# rCSL_emac_001 register map
Vendor: Texas Instruments
Peripheral module from a debugger description file (folder OMAPL138_C6748).
Registers are 32-bit, read-write, reset 0x0 unless marked. A register's access mark holds for its fields unless they carry their own. Offsets are as the file gives them; lines under a group give offsets from that group; [hi:lo] are bit positions; {n}, {i} and the like mark numbered series; 'fields as' and 'values as' point back to an identical list; <NAME> marks a mode.

## EMAC — Common Platform Gigabit ethernet MAC
0x00 TXREVID ro reset 0x4EC0020D — Transmit Identification and Version Register
  [31:0] TXREV
0x04 TXCONTROL access not given — Transmit Control Register
  [0] TXEN rw — Transmit enable
    0=DISABLE (Transmit is disabled); 1=ENABLE (Transmit is enabled)
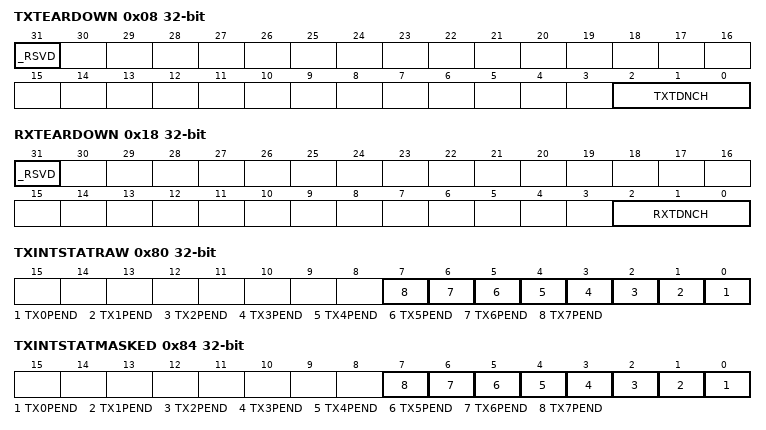
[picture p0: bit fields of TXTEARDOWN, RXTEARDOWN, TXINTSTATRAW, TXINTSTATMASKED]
0x08 TXTEARDOWN access not given — Transmit Teardown Register
  [31] _RSVD — TX teardown ready; read as zero, but always assumed to be one - unused (access N)
  [2:0] TXTDNCH rw — TX teardown channed
    {v}=CHA{v} (v=0..7)
0x10 RXREVID ro reset 0x4EC0020D — RX Identification and Version Register
  [31:0] RXREV
0x14 RXCONTROL access not given
  [0] RXEN rw — RX DMA enable
    0=DISABLE (Receive is disabled); 1=ENABLE (Receive is enabled)
0x18 RXTEARDOWN access not given
  [31] _RSVD — Teardown ready; read as zero, but it is always assumed to be one - unused (access N)
  [2:0] RXTDNCH rw — RX teardown channel
    {v}=CHA{v} (v=0..7)
0x80 TXINTSTATRAW access not given — Transmit Interrupt Status Register
  [n] TX{n}PEND ro (n=0..7) — TX{n}PEND raw interrupt read (before mask)
0x84 TXINTSTATMASKED access not given — Transmit Interrupt Status Register Masked
  [n] TX{n}PEND ro (n=0..7) — TX{n}PEND masked interrupt read
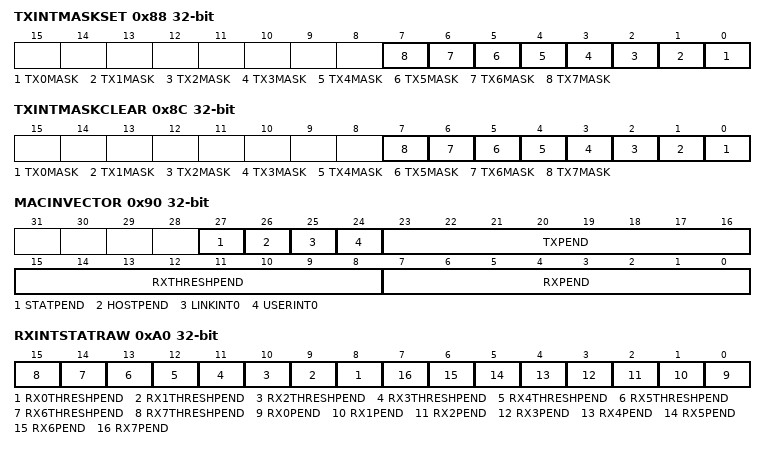
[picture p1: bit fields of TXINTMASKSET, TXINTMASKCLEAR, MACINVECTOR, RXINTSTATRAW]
0x88 TXINTMASKSET access not given — Transmit Interrupt Mask Set Register
  [n] TX{n}MASK rw (n=0..7) — TX channel {n} interrupt pending mask set bit - Write one to enable
0x8C TXINTMASKCLEAR access not given — Transmit Interrupt Clear Register
  [n] TX{n}MASK rw (n=0..7) — TX channel {n} interrupt pending mask set bit - Write one to disable
0x90 MACINVECTOR access not given — MAC Input Vector Register
  [27] STATPEND ro — Status Pending
  [26] HOSTPEND ro — Host Pending
  [25] LINKINT0 ro — MDIO Link Int
  [24] USERINT0 ro — MDIO User Int
  [23:16] TXPEND ro — TX Pend[7:0]
  [15:8] RXTHRESHPEND ro — RX Thresh Pend[7:0]
  [7:0] RXPEND ro — RX Pend[7:0]
0x94 MACEOIVECTOR access not given — MAC End of Interrupt Vector
  [4:0] INTVECT rw — MAC End of Interrupt Vector; reflects the value written to this location one VBUSP_CLK cycle after a write to this location.
    0=C0RXTHRESH; 1=C0RX; 2=C0TX; 3=C0MISC; 4=C1RXTHRESH; 5=C1RX; 6=C1TX; 7=C1MISC
0xA0 RXINTSTATRAW access not given — Receive Interrupt Status Register Raw
  [n+8] RX{n}THRESHPEND ro (n=0..7) — RX{n}THRESHPEND raw interrupt read (before mask)
  [n] RX{n}PEND ro (n=0..7) — RX{n}PEND raw interrupt read (before mask)
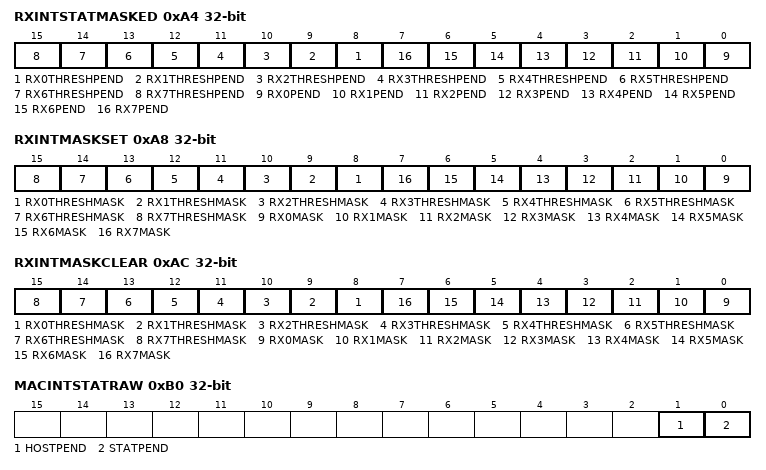
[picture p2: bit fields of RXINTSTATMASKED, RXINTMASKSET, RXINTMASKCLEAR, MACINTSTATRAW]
0xA4 RXINTSTATMASKED access not given — Receive Interrupt Status Register Masked
  [n+8] RX{n}THRESHPEND ro (n=0..7) — RX{n}THRESHPEND masked interrupt read
  [n] RX{n}PEND ro (n=0..7) — RX{n}PEND masked interrupt read
0xA8 RXINTMASKSET access not given — Receive Interrupt Mask Set Register
  [n+8] RX{n}THRESHMASK rw (n=0..7) — Receive Channel {n} Threshold Pending Mask; write one to enable interrupt
  [n] RX{n}MASK rw (n=0..7) — Receive Channel {n} Pending Mask; write one to enable interrupt
0xAC RXINTMASKCLEAR access not given — Receive Interrupt Mask Clear Register
  [n+8] RX{n}THRESHMASK rw (n=0..7) — Receive Channel {n} Threshold Pending Mask; write one to disable interrupt
  [n] RX{n}MASK rw (n=0..7) — Receive Channel {n} Pending Mask; write one to disable interrupt
0xB0 MACINTSTATRAW access not given — MAC Interrupt Status Register Raw (Unmasked)
  [1] HOSTPEND ro — Host pending interrupt; raw interrupt read (before mask)
  [0] STATPEND ro — Statistics pending interrupt; raw interrupt read (before mask)
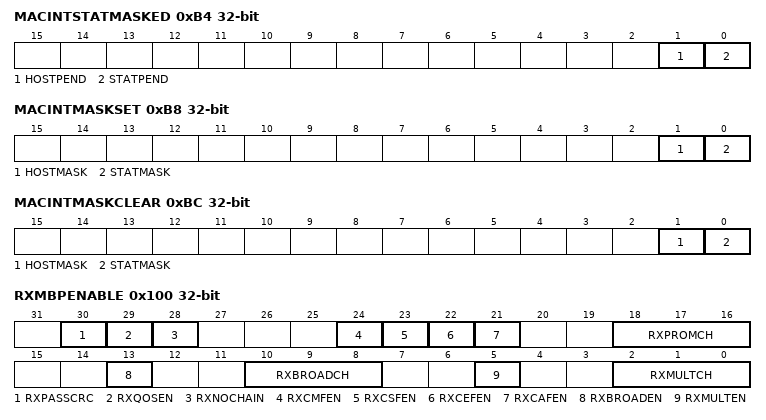
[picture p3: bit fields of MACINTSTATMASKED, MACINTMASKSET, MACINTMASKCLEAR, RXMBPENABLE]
0xB4 MACINTSTATMASKED access not given — MAC Interrupt Status Register Masked
  [1] HOSTPEND ro — Host pending interrupt; masked interrupt read
  [0] STATPEND ro — Statistics pending interrupt; masked interrupt read
0xB8 MACINTMASKSET access not given — MAC Interrupt Mask Set Register
  [1] HOSTMASK rw — Host error interrupt mask; write one to enable interrupt
  [0] STATMASK rw — Statistics interrupt;mask; write one to enable interrupt
0xBC MACINTMASKCLEAR access not given — MAC Interrupt Mask Clear Register
  [1] HOSTMASK rw — Host error interrupt mask; write one to disable interrupt
  [0] STATMASK rw — Statistics interrupt;mask; write one to disable interrupt
0x100 RXMBPENABLE access not given — Receive Multicast/Broadcast/Promiscuous Channel Enable Register
  [30] RXPASSCRC rw — Pass receive CRC enable
    0=DISCARD (Received CRC is discarded for all channels and is not included in the buffer descriptor packet length field); 1=INCLUDE (Received CRC is transferred to memory for all channels and is included in the buffer descriptor packet length)
  [29] RXQOSEN rw — Receive quality of service enable
    0=DISABLE (Receive QOS is disabled); 1=ENABLE (Receive QOS is enabled)
  [28] RXNOCHAIN rw — Receive no buffer chaining
    0=DISABLE (Received frames can span multiple buffers); 1=ENABLE (RX DMA controller transfers each frame into a single buffer regardless of the frame or buffer size. All remaining frame data after the first buffer is discarded)
  [24] RXCMFEN rw — Receive copy MAC control frames enable
    0=DISABLE (MAC control frames are filtered (but acted upon if enabled)); 1=ENABLE (MAC control frames are transferred to memory)
  [23] RXCSFEN rw — Receive copy short frames enable
    0=DISABLE (Short frames are filtered); 1=ENABLE (Short frames are transferred to memory)
  [22] RXCEFEN rw — Receive copy error frames enable
    0=DISABLE (Frames containing errors are filtered); 1=ENABLE (Frames containing errors are transferred to memory)
  [21] RXCAFEN rw — Receive copy all frames enable
    0=DISABLE; 1=ENABLE (Frames that do not address match are transferred to the promiscuous channel selected by RXPROMCH bits)
  [18:16] RXPROMCH rw — Receive promiscuous channel select
    {v}=CHA{v} (v=0..7)
  [13] RXBROADEN rw — Receive broadcast enable
    0=DISABLE (Broadcast frames are filtered); 1=ENABLE (Broadcast frames are copied to the channel selected by RXBROADCH bits)
  [10:8] RXBROADCH rw — Receive broadcast channel select
    {v}=CHA{v} (v=0..7)
  [5] RXMULTEN rw — RX multicast enable
    0=DISABLE (Multicast frames are filtered); 1=ENABLE (Multicast frames are copied to the channel selected by RXMULTCH bits)
  [2:0] RXMULTCH rw — RX multicast channel select
    {v}=CHA{v} (v=0..7)
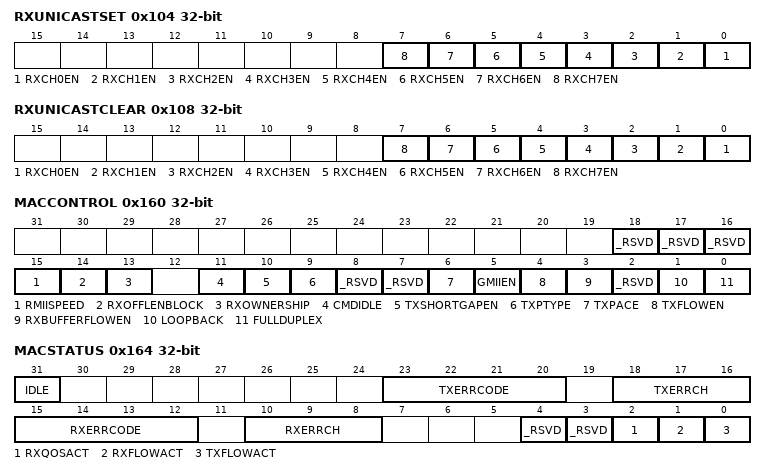
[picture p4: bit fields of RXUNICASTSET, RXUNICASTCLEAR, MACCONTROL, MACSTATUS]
0x104 RXUNICASTSET access not given — Receive Unicast Enable Set Register
  [all] fields
    1=SET
  [n] RXCH{n}EN rw (n=0..7) — RX channel {n} unicast enable set
0x108 RXUNICASTCLEAR access not given — Receive Unicast Clear Register
  [all] fields
    1=CLEAR
  [n] RXCH{n}EN rw (n=0..7) — RX channel {n} unicast enable clear
0x10C RXMAXLEN access not given reset 0x5EE — Receive Maximum Length Register
  [15:0] RXMAXLEN rw — RX maximum frame length
0x110 RXBUFFEROFFSET access not given — Receive Buffer Offset Register
  [15:0] RXBUFFEROFFSET rw — RX buffer offset value
0x114 RXFILTERLOWTHRESH access not given — Receive Filter Low Priority Frame Threshold Register
  [7:0] RXFILTERTHRESH rw — RX filter low threshold
{0x120+4i} RX{i}FLOWTHRESH access not given (i=0..7) — Receive Channel {i} Flow Control Threshold Register
  [7:0] RX{i}FLOWTHRESH rw — RX flow threshold
{0x140+4i} RX{i}FREEBUFFER access not given (i=0..7) — Receive Channel {i} Free Buffer Count Register
  [15:0] RX{i}FREEBUF wo — RX free buffer count; Write to increment
0x160 MACCONTROL access not given
  [18] _RSVD — Enables external select of Dupex/Gigabit modes (access N)
  [17] _RSVD — Gigabit force mode (access N)
  [16] _RSVD — Interface Control B (access N)
  [15] RMIISPEED rw — RMII 10/100 Speed Select (IFCTLA)
    0=10MBIT; 1=100MBIT
  [14] RXOFFLENBLOCK rw — Receive Offset / Length word write block
    0=NOBLOCK (Do not block the DMA writes to the receive buffer descriptor offset/buffer length word); 1=BLOCK (Block all EMAC DMA controller writes to the receive buffer descriptor offset/buffer length words during CPPI packet processing. When this bit is set, the EMAC will never write the third word to any receive buffer descriptor)
  [13] RXOWNERSHIP rw — Receive ownership write bit value
    0=ZERO (The EMAC writes the RX ownership bit to zero at the end of packet processing); 1=ONE (The EMAC writes the RX ownership bit to one at the end of packet processing)
  [11] CMDIDLE rw — Command Idle
    0=DISABLE (Idle not commanded); 1=ENABLE (Idle commanded (read IDLE is MACSTATUS))
  [10] TXSHORTGAPEN rw — Transmit short gap enable
    0=DISABLE (TX with a short IPG is disabled); 1=ENABLE (TX with a short IPG (when TX_HSORT_GAP input is asserted) is enabled)
  [9] TXPTYPE rw — Transmit queue priority type
    0=RROBIN (The queue uses a round-robin scheme to select the next channel for transmission); 1=CHANNELPRI (The queue uses a fixed-priority (channel 7 highest priority) scheme to select the next channel for transmission)
  [8] _RSVD — FIFO RAM processor read/write enable (RAM test mode) (access N)
  [7] _RSVD — Gigabit mode (access N)
  [6] TXPACE rw — Transmit pacing enable
    0=DISABLE (TX pacing is disabled); 1=ENABLE (TX pacing is enabled)
  [5] GMIIEN rw — GMII enable
    0=DISABLE (GMII RX and TX are held in reset); 1=ENABLE (GMII RX and TX are released from reset)
  [4] TXFLOWEN rw — Transmit flow control enable
    0=DISABLE (TX flow control is disabled. Full-duplex mode: incoming pause frames are not acted upon); 1=ENABLE (TX flow control is enabled. Full-duplex mode: incoming pause frames are acted upon)
  [3] RXBUFFERFLOWEN rw — Receive buffer flow control enable
    0=DISABLE (RX flow control is disabled. Half-duplex mode: no flow control generated collisions are sent. Full-duplex mode: no outgoing pause frames are sent); 1=ENABLE (RX flow control is enabled. Half-duplex mode: collisions are initiated when receive flow control is triggered. Full-duplex mode: outgoing pause frames are sent when receive flow control is triggered)
  [2] _RSVD — Manufacturing test mode (access N)
  [1] LOOPBACK rw — Loopback mode
    0=DISABLE (Loopback mode is disabled); 1=ENABLE (Loopback mode is enabled)
  [0] FULLDUPLEX rw — Full duplex mode; gigabit mode forces full duplex mode regardless of whether the fullduplex bit isset or not
    0=HALFDUPLEX (Half-duplex mode); 1=FULLDUPLEX (Full-duplex mode)
0x164 MACSTATUS access not given
  [31] IDLE ro — CPGMAC idle
    0=NOIDLE (The EMAC is not idle); 1=IDLE (The EMAC is in the idle state)
  [23:20] TXERRCODE ro — TX host error code
    0=NOERROR; 1=SOPERROR; 2=OWNERSHIP (Ownership bit not set in SOP buffer); 3=NOEOP (Zero next buffer descriptor pointer without EOP); 4=NULLPTR (Zero buffer pointer); 5=NULLEN (Zero buffer length); 6=LENERROR (Packet length error (sum of buffers < packet length))
  [18:16] TXERRCH ro — TX host error channel
    {v}=CHA{v} (v=0..7)
  [15:12] RXERRCODE ro — RX host error code
    0=NOERROR; 2=OWNERSHIP (Ownership bit not set in SOP buffer); 4=NULLPTR (Zero buffer pointer)
  [10:8] RXERRCH ro — RX host error channel
    {v}=CHA{v} (v=0..7)
  [4] _RSVD — (access N)
  [3] _RSVD — (access N)
  [2] RXQOSACT ro — RX Quality of Service active
    0=DISABLE; 1=ENABLE
  [1] RXFLOWACT ro — RX flow control active
    0=INACTIVE; 1=ACTIVE
  [0] TXFLOWACT ro — TX flow control active
    0=INACTIVE; 1=ACTIVE
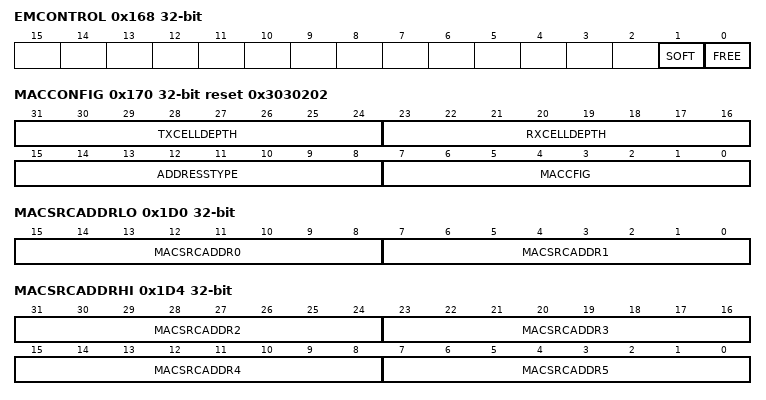
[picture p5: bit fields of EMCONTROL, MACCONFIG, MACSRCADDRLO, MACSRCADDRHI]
0x168 EMCONTROL access not given — Emulation Control Register
  [1] SOFT rw — Emulation soft bit
  [0] FREE rw — Emulation free bit
0x16C FIFOCONTROL access not given reset 0x2
  [1:0] TXCELLTHRESH rw — TX FIFO cell threshold
0x170 MACCONFIG ro reset 0x3030202 — MAC Configuration Register
  [31:24] TXCELLDEPTH — TX cell depth - the number of cells in the transmit FIFO
  [23:16] RXCELLDEPTH — RX cell depth - the number of cells in the receive FIFO
  [15:8] ADDRESSTYPE — Address type in the design
  [7:0] MACCFIG — MAC configuration value
0x174 SOFTRESET access not given
  [0] SOFTRESET rw — Software reset
    0=NORESET; 1=RESET
0x1D0 MACSRCADDRLO access not given — MAC Source Address Low
  [15:8] MACSRCADDR0 rw — MAC source address lower 8 bits MACADDR[7:0]
  [7:0] MACSRCADDR1 rw — MAC source address bits 15:9 MACADDR[15:8]
0x1D4 MACSRCADDRHI — MAC Source Address High
  [31:24] MACSRCADDR2 — MAC source address bits 23:16 (byte 2)
  [23:16] MACSRCADDR3 — MAC source address bits 31:23 (byte 3)
  [15:8] MACSRCADDR4 — MAC source address bits 39:32 (byte 4)
  [7:0] MACSRCADDR5 — MAC source address bits 47:40 (byte 5)
0x1D8 MACHASH1 — MAC Hash Address Register 1
  [31:0] MACHASH1 — Least-significant 32 bits of the hash table corresponding to hash values 0 to 31
0x1DC MACHASH2 — MAC Hash Address Register 2
  [31:0] MACHASH2 — Most-significant 32 bits of the hash table corresponding to hash values 32 to 63
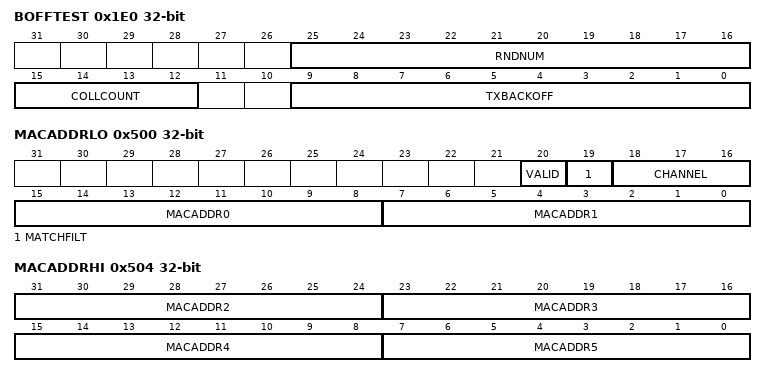
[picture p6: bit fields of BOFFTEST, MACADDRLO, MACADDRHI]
0x1E0 BOFFTEST access not given — Back Off Test Register
  [25:16] RNDNUM rw — Backoff random number generator
  [15:12] COLLCOUNT ro — Collision count
  [9:0] TXBACKOFF ro — Backoff count
0x1E4 TPACETEST access not given — Transmit Pacing Algorithm Test Register
  [4:0] PACEVAL ro — Pacing register current value
0x1E8 RXPAUSE access not given — Receive Pause Timer Register
  [15:0] PAUSETIMER rw — RX pause timer value
0x1EC TXPAUSE access not given — Transmit Pause Timer Register
  [15:0] PAUSETIMER rw — TX pause timer value
0x200 RXGOODFRAMES — Good RX Frames
  [31:0] COUNT
0x204 RXBCASTFRAMES — Total number of good broadcast frames received
  [31:0] COUNT
0x208 RXMCASTFRAMES — Total number of good multicast frames received
  [31:0] COUNT
0x20C RXPAUSEFRAMES — Pause RX Frames Register
  [31:0] COUNT
0x210 RXCRCERRORS — Total number of frames received with CRC errors
  [31:0] COUNT
0x214 RXALIGNCODEERRORS — Total number of frames received with alignment/code errors
  [31:0] COUNT
0x218 RXOVERSIZED — Total number of oversized frames received
  [31:0] COUNT
0x21C RXJABBER — Total number of jabber frames received
  [31:0] COUNT
0x220 RXUNDERSIZED — Total number of undersized frames received
  [31:0] COUNT
0x224 RXFRAGMENTS — RX Frame Fragments Register
  [31:0] COUNT
0x228 RXFILTERED — Filtered Receive Frames
  [31:0] COUNT
0x22C RXQOSFILTERED — Received Frames Filtered by QOS
  [31:0] COUNT
0x230 RXOCTETS — Total number of received bytes in good frames
  [31:0] COUNT
0x234 TXGOODFRAMES — Total number of good frames transmitted
  [31:0] COUNT
0x238 TXBCASTFRAMES — Broadcast TX Frames Register
  [31:0] COUNT
0x23C TXMCASTFRAMES — Multicast TX Frames Register
  [31:0] COUNT
0x240 TXPAUSEFRAMES — Pause TX Frames Register
  [31:0] COUNT
0x244 TXDEFERRED — Deferred TX Frames Register
  [31:0] COUNT
0x248 TXCOLLISION — TX Collision Frames Register
  [31:0] COUNT
0x24C TXSINGLECOLL — TX Single Collision Frames Register
  [31:0] COUNT
0x250 TXMULTICOLL — TX Multiple Collision Frames Register
  [31:0] COUNT
0x254 TXEXCESSIVECOLL — TX Excessive Collision Frames Register
  [31:0] COUNT
0x258 TXLATECOLL — TX Late Collision Frames Register
  [31:0] COUNT
0x25C TXUNDERRUN — TX Underrun Error Register
  [31:0] COUNT
0x260 TXCARRIERSENSE — TX Carrier Sense Errors Register
  [31:0] COUNT
0x264 TXOCTETS — TX Octet Frames Register
  [31:0] COUNT
0x268 FRAME64 — Transmit and Receive 64 Octet Frames Register
  [31:0] COUNT
0x26C FRAME65T127 — Transmit and Receive 65 to 127 Octet Frames Register
  [31:0] COUNT
0x270 FRAME128T255 — Transmit and Receive 128 to 255 Octet Frames Register
  [31:0] COUNT
0x274 FRAME256T511 — Transmit and Receive 256 to 511 Octet Frames Register
  [31:0] COUNT
0x278 FRAME512T1023 — Transmit and Receive 512 to 1023 Octet Frames Register
  [31:0] COUNT
0x27C FRAME1024TUP — Transmit and Receive 1024 to 1518 Octet Frames Register
  [31:0] COUNT
0x280 NETOCTETS — Network Octet Frames Register
  [31:0] COUNT
0x284 RXSOFOVERRUNS — Receive FIFO or DMA Start of Frame Overruns Register
  [31:0] COUNT
0x288 RXMOFOVERRUNS — Receive FIFO or DMA Middle of Frame Overruns Register
  [31:0] COUNT
0x28C RXDMAOVERRUNS — Receive DMA Start of Frame and Middle of Frame Overruns Register
  [31:0] COUNT
0x500 MACADDRLO access not given — MAC Address Low - From Receive Address Matching Memory Map
  [20] VALID rw
    0=INVALID; 1=VALID
  [19] MATCHFILT rw
    0=FILTER; 1=MATCH
  [18:16] CHANNEL rw
  [15:8] MACADDR0 rw — MAC addres lower 8 bits (byte 0)
  [7:0] MACADDR1 rw — MAC addres bits 15:8 (byte 1)
0x504 MACADDRHI — MAC Address High - Receive Address Matching
  [31:24] MACADDR2 — MAC source address bits 23:16 (byte 2)
  [23:16] MACADDR3 — MAC source address bits 31:23 (byte 3)
  [15:8] MACADDR4 — MAC source address bits 39:32 (byte 4)
  [7:0] MACADDR5 — MAC source address bits 47:40 (byte 5)
0x508 MACINDEX access not given
  [4:0] MACINDEX rw — MAC address index
{0x600+4i} TX{i}HDP (i=0..7) — Transmit Channel {i} DMA Head Descriptor Pointer Register
  [31:0] TX{i}HDP — TX channel {i} DMA Head Descriptor pointer
{0x620+4i} RX{i}HDP (i=0..7) — Receive Channel {i} DMA Head Descriptor Pointer Register
  [31:0] RX{i}HDP — RX channel {i} DMA Head Descriptor pointer
0x640 TX0CP — Transmit Channel 0 Completion Pointer (Interrupt Ack) Register
  [31:0] TX0CP — TX channel 0 completion pointer register
{0x640+4i} TX{i}CP (i=1..7) — Transmit Channel {i} Completion Pointer Register
  [31:0] TX{i}CP — TX channel {i} completion pointer register
{0x660+4i} RX{i}CP (i=0..7) — Receive Channel {i} Completion Pointer (Interrupt Ack) Register
  [31:0] RX{i}CP — RX channel {i} completion pointer register
